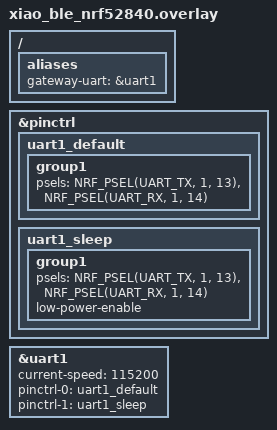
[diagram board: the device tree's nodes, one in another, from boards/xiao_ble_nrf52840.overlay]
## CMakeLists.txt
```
# SPDX-License-Identifier: Apache-2.0

cmake_minimum_required(VERSION 3.20.0)
find_package(Zephyr REQUIRED HINTS $ENV{ZEPHYR_BASE})
project(pawr_central)

target_sources(app PRIVATE
    src/main.c
    src/gateway_uart_tx.c
    src/gui_uart_tx.c
    ../common/uart_frame.c
    ../common/sensor_log.c
    ../common/watchdog.c
)
target_include_directories(app PRIVATE ${CMAKE_CURRENT_SOURCE_DIR}/../common ${CMAKE_CURRENT_SOURCE_DIR})
```

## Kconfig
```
# SPDX-License-Identifier: Apache-2.0

mainmenu "PAwR central hub"

config APP_CENTRAL_ID
	int "This central's ID (0 = default/unscoped)"
	default 0
	range 0 999
	help
	  Only peripherals advertising a matching CONFIG_APP_CENTRAL_ID suffix
	  (see PAWR_ADV_NAME/pawr_format_adv_name() in common/pawr_protocol.h)
	  will be onboarded by this central -- lets multiple independent
	  central+peripheral-fleet rigs run in BLE range of each other without
	  cross-onboarding each other's peripherals. 0 means "unscoped": scans
	  for the bare PAWR_ADV_NAME with no suffix, matching peripherals that
	  also have CONFIG_APP_CENTRAL_ID=0 (the default, preserves old
	  single-central behavior with no config changes needed).

config APP_DUMP_LOG_ON_BOOT
	bool "Dump the on-board flash sensor log as CSV over serial at boot"
	default n
	help
	  One-shot retrieval mode: at boot, print every payload recorded in
	  the on-board flash log (see common/sensor_log.h) as CSV over
	  printk(), then continue normal operation as usual. Same mechanism
	  as peripheral's CONFIG_APP_DUMP_ON_BOOT -- capture serial output
	  right after boot to retrieve the CSV.

source "Kconfig.zephyr"
```

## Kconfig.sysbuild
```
#
# SPDX-License-Identifier: Apache-2.0
#

config NRF_DEFAULT_IPC_RADIO
	default y

config NETCORE_IPC_RADIO_BT_HCI_IPC
	default y

source "share/sysbuild/Kconfig"
```

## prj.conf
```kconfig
CONFIG_BT=y
CONFIG_BT_BROADCASTER=y
CONFIG_BT_EXT_ADV=y
CONFIG_BT_PER_ADV=y
CONFIG_BT_DEVICE_NAME="PAwR adv sample"

# NOTE: Coded PHY support (CONFIG_BT_CTLR_PHY_CODED) is intentionally NOT
# set here -- an earlier LE Coded PHY implementation was removed 2026-08-11
# after real hardware repeatedly failed to sync with it, root cause never
# found (see NOTES.md and common/pawr_protocol.h).

CONFIG_BT_MAX_CONN=1
CONFIG_BT_CENTRAL=y
CONFIG_BT_PER_ADV_SYNC_TRANSFER_SENDER=y

CONFIG_BT_PER_ADV_RSP=y

# 2026-08-09: briefly overrode CONFIG_BT_CTLR_SDC_PERIODIC_ADV_EVENT_LEN_DEFAULT
# (default 7500us) to 1500000us as a diagnostic step while chasing a PAST
# sync failure at NUM_SUBEVENTS=34 -- made no difference, reverted. See
# NOTES.md 2026-08-09 -- this was never the actual variable either.

# SoftDevice Controller defaults for PAwR response buffering are sized for a
# light workload (TX=3, RX=2) and don't auto-scale with NUM_SUBEVENTS -- see
# NOTES.md 2026-08-01. Confirmed a real ~2.7x improvement (28.7% -> 10.6%
# miss rate) at 10 subevents over a 30-min soak. 6/6 was confirmed stable at
# 20-subevent scale over a full 30-min soak (also NOTES.md 2026-08-01), and
# held up at 5 concurrent real nodes for a full hour (NOTES.md 2026-08-03) --
# the one instability seen there traced to a single physical peripheral, not
# this config.
#
# 2026-08-04: NUM_SUBEVENTS was temporarily raised 20 -> 55 for a 50-node
# deployment target, and these buffer counts were bumped to an untested 15/15
# linear guess to match -- flagged at the time as unvalidated, and never
# actually soak-tested at 55 subevents (see the 2026-08-05 22-node session:
# 69.74% PDR with multi-node dropout patterns consistent with that warning).
#
# 2026-08-07: reverted to 20 subevents / 17-node deployment target (see
# common/pawr_protocol.h) -- so these revert to 6/6 too, back to the value
# that's actually soak-tested at this exact subevent count, instead of
# carrying the unvalidated 15/15 guess forward for no reason.
#
# 2026-08-07 (later same day): tried stepping 6/6 -> 8/8 as an incremental
# probe for whether more buffering improves PDR at ~14-17 real concurrent
# nodes -- REVERTED, 8/8 made things worse, not better. Raw received-packet
# PDR on the nodes that did report looked fine (90.45% over ~10 min, 11
# nodes, no in-window dropouts) -- but per-node PDR only measures nodes that
# are already reporting, and it hid the real problem: 3 of the 16
# previously-connected nodes (47, 58, 63) never re-onboarded after this
# build was flashed, even 15+ minutes later, while 13/16 reconnected fine.
# This is a milder version of the same failure NOTES.md 2026-08-01 saw at
# 12/12 (there, total failure -- zero output for a full 30-min soak): some
# nodes silently fail to (re-)onboard rather than an obvious crash/hang, so
# per-node PDR alone is NOT sufficient to judge a buffer-count change --
# always also compare the full set of node IDs seen before vs. after.
# Reverted to 6/6, the only value actually confirmed clean at 20 subevents
# (1 node/30min + 5 nodes/1hr soaks, NOTES.md 2026-08-01 and 2026-08-03).
# If buffer-count tuning is revisited, treat both PDR AND "did every
# previously-connected node actually come back" as required, equally-weighted
# signals -- not just the received/expected ratio.
#
# 2026-08-07 (empirical test, stated explicitly as a test not a considered
# recommendation): tried 4/4 -- REVERTED. All 13 previously-active nodes did
# reconnect cleanly this time (no repeat of 8/8's reconnect-stall symptom),
# but overall PDR dropped to 86.82% (vs 8/8's 90.45% among the nodes that
# reported), with two nodes notably worse than their usual range (node 54:
# 41.2%, node 56: 77.4%). Matches the predicted direction from the
# 2026-08-01 history (SDK default 3/2 already gave 28.7% miss rate at half
# this subevent count) -- going below 6 trades "does everyone reconnect" for
# "how reliably do already-synced nodes get through," not a clean win.
# Back to 6/6 -- still the only value with real positive multi-hour evidence
# on both axes (full node-set recovery AND PDR) at this subevent count.
CONFIG_BT_CTLR_SDC_PERIODIC_ADV_RSP_TX_BUFFER_COUNT=6
CONFIG_BT_CTLR_SDC_PERIODIC_ADV_RSP_RX_BUFFER_COUNT=6

# Max native TX power for the nRF52840 radio (no external front-end amp on
# the XIAO board) -- default is 0 dBm. distance-test-17slot branch's
# 2026-08-08 distance sweep showed PDR dropping to 71-82% by 1.5-2m at
# 0dBm; +8 dBm alone brought 1m from 82.4% to 96.9%, 1.5m from 71.0% to
# 91.9%, 2m from 78.3% to 89.0%. The single biggest, cheapest improvement
# found this session -- folded in here as a baseline change. Must be set
# the same on BOTH central and peripheral -- see the matching line in
# peripheral/prj.conf.
#
# 2026-08-09: a long false alarm chased +8dBm as the cause of a PAST sync
# failure at NUM_SUBEVENTS=34 -- suspected at the time to be an unrelated
# Coded-PHY refactor stack-usage bug plus transient board/USB state.
# Confirmed clean at the time: 30-min soak, full 17-node fleet, +8dBm, 34
# subevents (redundant slots) -- 99.47% PDR, zero dropouts, a real ~2.7pp
# improvement over the 96.79% 0dBm baseline. Full writeup in NOTES.md
# 2026-08-09 and logs/2026-08-09_sync_failure_investigation.md.
#
# 2026-08-11: reintroduced carefully, one change at a time, on top of the
# confirmed-working aba6a56 checkpoint (see NOTES.md) after losing track of
# which combination of changes was actually causing sync problems. +8dBm
# alone, re-isolated and re-confirmed working on real hardware. The Coded
# PHY refactor was ALSO re-tried on top of it, this time with a
# byte-verified-identical stack frame to the known-working build -- it
# still broke sync, disproving the 2026-08-09 stack-usage theory above.
# Root cause still unknown; Coded PHY is excluded going forward. +8dBm
# itself remains the one real, reproducible contributor to the PDR
# improvement.
CONFIG_BT_CTLR_TX_PWR_PLUS_8=y

CONFIG_BT_REMOTE_INFO=y
CONFIG_BT_GATT_CLIENT=y

CONFIG_LOG=y

CONFIG_GPIO=y

# UART1 link to the nRF9151 gateway board (see boards/xiao_ble_nrf52840.overlay
# and ../gateway_9151) -- separate physical UART from the console (uart0,
# USB-CDC-ACM), so this doesn't compete with printk output.
CONFIG_SERIAL=y
CONFIG_UART_INTERRUPT_DRIVEN=y

# On-board flash log (Flash Circular Buffer) -- fallback record of every
# sensor_payload received over PAwR, in case the UART link to the gateway
# board or the gateway's own MQTT/LTE hop is down. Same partition mechanism
# as peripheral/prj.conf (see that file's comment: CONFIG_FCB only "depends
# on" FLASH_MAP, doesn't "select" it, so FLASH_MAP must be turned on
# explicitly too). See common/sensor_log.c.
CONFIG_FLASH=y
CONFIG_FLASH_MAP=y
CONFIG_FCB=y

# Hardware watchdog (2026-08-30, see watchdog.c): last-resort recovery for a
# central wedged by a bug in the onboarding retry loop (a real one was found
# and fixed the same day -- see device_found()'s bt_conn_le_create() failure
# comment -- but a hardware WDT is defense-in-depth against that class of
# bug generally, not just the one instance already fixed). Fed only when the
# main loop provably makes forward progress (successfully (re)starts
# scanning), not on a fixed timer -- a timer-based feed from an unrelated
# thread would keep feeding even while the main loop itself is wedged,
# defeating the whole point.
CONFIG_WATCHDOG=y
```

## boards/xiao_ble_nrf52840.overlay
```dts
/*
 * Enables the XIAO BLE's second UART controller (uart1) for the wired link
 * to the nRF9151 gateway board -- separate from uart0/xiao_serial, which is
 * this board's console (routed to USB-CDC-ACM; see zephyr.dts
 * zephyr,console = &board_cdc_acm_uart) and physically occupies D6/D7
 * (P1.11/P1.12, per xiao_ble-pinctrl.dtsi's uart0_default). D4/D5 are
 * already committed to the I2C sensor bus (see peripheral's overlay). That
 * leaves D8/D9 (P1.13/P1.14) as the first free pin pair -- used here for
 * uart1 TX/RX.
 *
 * Wiring: XIAO D8 (TX) -> 9151 DK UART RX, XIAO D9 (RX) -> 9151 DK UART TX,
 * plus a shared GND between the two boards. Confirm the 9151 DK's chosen
 * UART instance/pins against its own overlay (gateway_9151/boards/) once
 * that's written -- the two ends must agree on which physical pins carry
 * TX vs RX (they cross over) and use the same baud rate (see
 * CONFIG_APP_UART_BAUDRATE in gateway_9151/Kconfig, default 115200).
 */

&pinctrl {
	uart1_default: uart1_default {
		group1 {
			psels = <NRF_PSEL(UART_TX, 1, 13)>,
				<NRF_PSEL(UART_RX, 1, 14)>;
		};
	};

	uart1_sleep: uart1_sleep {
		group1 {
			psels = <NRF_PSEL(UART_TX, 1, 13)>,
				<NRF_PSEL(UART_RX, 1, 14)>;
			low-power-enable;
		};
	};
};

&uart1 {
	status = "okay";
	current-speed = <115200>;
	pinctrl-0 = <&uart1_default>;
	pinctrl-1 = <&uart1_sleep>;
	pinctrl-names = "default", "sleep";
};

/ {
	aliases {
		gateway-uart = &uart1;
	};
};
```

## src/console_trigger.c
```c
/*
 * Copyright (c) 2026
 *
 * SPDX-License-Identifier: Apache-2.0
 */

#include <zephyr/device.h>
#include <zephyr/devicetree.h>
#include <zephyr/drivers/uart.h>
#include <zephyr/sys/printk.h>

#include "console_trigger.h"

/* zephyr,console already resolves to this board's own USB-CDC-ACM console
 * device (confirmed via the generated devicetree) -- the same physical
 * connection printk() output already uses, so no new wiring/hardware.
 */
#define CONSOLE_UART_NODE DT_CHOSEN(zephyr_console)

static const struct device *const console_uart_dev = DEVICE_DT_GET(CONSOLE_UART_NODE);

static void console_uart_isr(const struct device *dev, void *user_data)
{
	console_trigger_byte_cb_t cb = user_data;
	uint8_t byte;

	while (uart_irq_update(dev) && uart_irq_rx_ready(dev)) {
		while (uart_fifo_read(dev, &byte, 1) == 1) {
			cb(byte);
		}
	}
}

int console_trigger_init(console_trigger_byte_cb_t cb)
{
	if (!device_is_ready(console_uart_dev)) {
		printk("[CONSOLE] Console device not ready, operator trigger disabled\n");
		return -ENODEV;
	}

	int err = uart_irq_callback_user_data_set(console_uart_dev, console_uart_isr, cb);

	if (err) {
		printk("[CONSOLE] Failed to set IRQ callback (err %d)\n", err);
		return err;
	}

	uart_irq_rx_enable(console_uart_dev);

	return 0;
}
```

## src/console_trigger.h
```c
/*
 * Copyright (c) 2026
 *
 * SPDX-License-Identifier: Apache-2.0
 *
 * Minimal operator-input mechanism over central's USB console (2026-08-13,
 * see common/pawr_protocol.h's file header for the GATT pivot this
 * supports): watches the console UART's RX for single trigger bytes so the
 * operator can switch central between INIT and DOWNLOAD mode without a
 * reflash. Deliberately NOT Zephyr's shell subsystem (CONFIG_SHELL) --
 * this project has repeatedly kept its own minimal, purpose-built code over
 * pulling in heavier subsystems (see e.g. common/uart_frame.h's own framing
 * instead of a generic protocol), and CONFIG_SHELL specifically hung this
 * project's console once before on the peripheral side (see NOTES.md
 * 2026-08-03) -- reason enough to avoid it here too, on the one board
 * that's actually meant to stay reachable/interactive throughout an
 * experiment.
 */

#ifndef CONSOLE_TRIGGER_H_
#define CONSOLE_TRIGGER_H_

#include <zephyr/kernel.h>

/* Called from UART ISR context for every byte received on the console --
 * keep this fast, no blocking calls (matches the ISR-callback pattern
 * already used by gateway_9151/src/uart/uart_receiver.c).
 */
typedef void (*console_trigger_byte_cb_t)(uint8_t byte);

/* Registers cb against the console UART's RX interrupt and enables RX.
 * Returns 0 on success, negative errno otherwise -- non-fatal to the rest
 * of the app if this fails (the operator just loses the ability to switch
 * modes at runtime; everything else keeps working).
 */
int console_trigger_init(console_trigger_byte_cb_t cb);

#endif /* CONSOLE_TRIGGER_H_ */
```

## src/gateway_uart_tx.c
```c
/*
 * Copyright (c) 2026
 *
 * SPDX-License-Identifier: Apache-2.0
 */

#include <zephyr/device.h>
#include <zephyr/devicetree.h>
#include <zephyr/drivers/uart.h>
#include <zephyr/sys/printk.h>

#include "gateway_uart_tx.h"
#include "uart_frame.h"

#define GATEWAY_UART_NODE DT_ALIAS(gateway_uart)

static const struct device *const gateway_uart_dev = DEVICE_DT_GET(GATEWAY_UART_NODE);
static bool gateway_uart_ready;

int gateway_uart_tx_init(void)
{
	if (!device_is_ready(gateway_uart_dev)) {
		printk("[GW-UART] Device not ready, sensor data will not be forwarded\n");
		return -ENODEV;
	}

	gateway_uart_ready = true;
	printk("[GW-UART] Ready\n");
	return 0;
}

void gateway_uart_tx_send(const struct sensor_payload *payload)
{
	if (!gateway_uart_ready) {
		return;
	}

	struct uart_frame frame = {
		.start = UART_FRAME_START_BYTE,
		.payload = *payload,
		.crc16 = uart_frame_crc16((const uint8_t *)payload, sizeof(*payload)),
	};

	/* uart_poll_out(), not uart_fifo_fill(): this is called from
	 * response_cb, a BLE callback context, not a UART TX ISR.
	 * uart_fifo_fill()'s own doc comment states "Result of calling this
	 * function not from an ISR is undefined (hardware-dependent)" --
	 * confirmed as the actual root cause of the gateway never receiving
	 * valid frames despite a real (non-zero) voltage on the wire (see
	 * NOTES.md 2026-08-04): TX was clocking bytes out through an
	 * unsupported code path instead of failing outright, producing
	 * malformed signaling. uart_poll_out() blocks until each byte is
	 * queued and is explicitly safe to call from any context. At 11
	 * bytes/frame and up to ~20 frames per ~10s interval, the blocking
	 * cost here is negligible.
	 */
	const uint8_t *bytes = (const uint8_t *)&frame;

	for (size_t i = 0; i < sizeof(frame); i++) {
		uart_poll_out(gateway_uart_dev, bytes[i]);
	}
}
```

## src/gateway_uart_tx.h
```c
/*
 * Copyright (c) 2026
 *
 * SPDX-License-Identifier: Apache-2.0
 *
 * Forwards each sensor_payload central receives from a peripheral out over
 * uart1 (see boards/xiao_ble_nrf52840.overlay) to the nRF9151 gateway board,
 * framed per ../common/uart_frame.h.
 */

#ifndef GATEWAY_UART_TX_H_
#define GATEWAY_UART_TX_H_

#include "pawr_protocol.h"

/* Initializes uart1. Returns 0 on success, negative errno otherwise. Safe to
 * call even if the gateway board isn't connected yet/at all -- TX just goes
 * nowhere in that case, this never blocks waiting for a peer.
 */
int gateway_uart_tx_init(void);

/* Frames and sends payload out over uart1. Called from response_cb, a hot
 * path (up to NUM_SUBEVENTS times per PAWR interval) -- keep this cheap;
 * it fills the UART's TX FIFO and returns, it does not block on the byte
 * actually leaving the wire.
 */
void gateway_uart_tx_send(const struct sensor_payload *payload);

#endif /* GATEWAY_UART_TX_H_ */
```

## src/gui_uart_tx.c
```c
/*
 * Copyright (c) 2026
 *
 * SPDX-License-Identifier: Apache-2.0
 */

#include <zephyr/device.h>
#include <zephyr/devicetree.h>
#include <zephyr/drivers/uart.h>
#include <zephyr/kernel.h>
#include <zephyr/sys/printk.h>

#include "gui_uart_tx.h"
#include "uart_frame.h"

/* zephyr,console on this board resolves to the USB CDC-ACM device (see
 * boards/xiao_ble_nrf52840.overlay's own comment: "this board's console,
 * routed to USB-CDC-ACM; zephyr,console = &board_cdc_acm_uart") -- the same
 * device printk's own output goes to, and the same one every capture tool
 * used throughout this project (capture_flash_dump.py, Watch-SerialLog.ps1)
 * already reads from.
 */
#define CONSOLE_UART_NODE DT_CHOSEN(zephyr_console)

static const struct device *const console_uart_dev = DEVICE_DT_GET(CONSOLE_UART_NODE);
static bool console_uart_ready;

int gui_uart_tx_init(void)
{
	if (!device_is_ready(console_uart_dev)) {
		printk("[GUI-UART] Console device not ready, direct-to-PC forwarding disabled\n");
		return -ENODEV;
	}

	console_uart_ready = true;
	printk("[GUI-UART] Direct-to-PC forwarding ready (shares console UART with this log)\n");
	return 0;
}

void gui_uart_tx_send(const struct sensor_payload *payload)
{
	if (!console_uart_ready) {
		return;
	}

	struct uart_frame frame = {
		.start = UART_FRAME_START_BYTE,
		.payload = *payload,
		.crc16 = uart_frame_crc16((const uint8_t *)payload, sizeof(*payload)),
	};
	const uint8_t *bytes = (const uint8_t *)&frame;

	/* This UART also carries printk's own text output, drained by a
	 * separate logging thread with no locking of its own (CONFIG_LOG_MODE_
	 * DEFERRED=y, confirmed in the built .config) -- without this lock,
	 * that thread could preempt partway through the loop below and
	 * interleave log-text bytes into the middle of a frame, corrupting it
	 * (the GUI's CRC check would catch and drop it, but that's a real lost
	 * reading, not just cosmetic). Identical reasoning/fix as
	 * gateway_9151/src/uart/gui_uart_tx.c's own k_sched_lock() -- see that
	 * file's comment for the full investigation. gateway_uart_tx.c doesn't
	 * need this because uart1 there is a dedicated wire, not shared with
	 * logging.
	 */
	k_sched_lock();

	for (size_t i = 0; i < sizeof(frame); i++) {
		uart_poll_out(console_uart_dev, bytes[i]);
	}

	k_sched_unlock();
}
```

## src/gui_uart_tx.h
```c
/*
 * Copyright (c) 2026
 *
 * SPDX-License-Identifier: Apache-2.0
 *
 * Direct-to-PC fallback (2026-08-30): forwards each sensor_payload central
 * receives out over its own USB console (the same CDC-ACM device printk's
 * output goes to), framed per ../../common/uart_frame.h -- identical wire
 * format to gateway_9151/src/uart/gui_uart_tx.c, so gui/sensor_gui.py's
 * existing UARTWorker can read a central directly with zero code changes on
 * the GUI side. Added for a rig whose gateway_9151 board's USB port had
 * failed: central was still receiving PAwR data fine, but nothing reached
 * the PC because gateway_9151 -> GUI was the only path that existed. This
 * is a second, independent path (not a replacement) -- central still also
 * forwards to gateway_9151 over uart1 via gateway_uart_tx.c, unaffected by
 * this addition.
 */

#ifndef GUI_UART_TX_H_
#define GUI_UART_TX_H_

#include "pawr_protocol.h"

/* Confirms the console UART device is ready. Returns 0 on success, negative
 * errno otherwise. Non-fatal to the rest of the app if this fails -- see
 * the call site in main.c.
 */
int gui_uart_tx_init(void);

/* Frames and sends payload out over the console UART, unconditionally.
 * Called from response_cb, the same hot path gateway_uart_tx_send() is
 * called from -- see that function's own comment on why uart_poll_out() is
 * required here (not uart_fifo_fill()) and gui_uart_tx.c's k_sched_lock()
 * comment for why this one (unlike gateway_uart_tx_send()) needs to guard
 * against interleaving with this device's own printk/logging output.
 */
void gui_uart_tx_send(const struct sensor_payload *payload);

#endif /* GUI_UART_TX_H_ */
```
